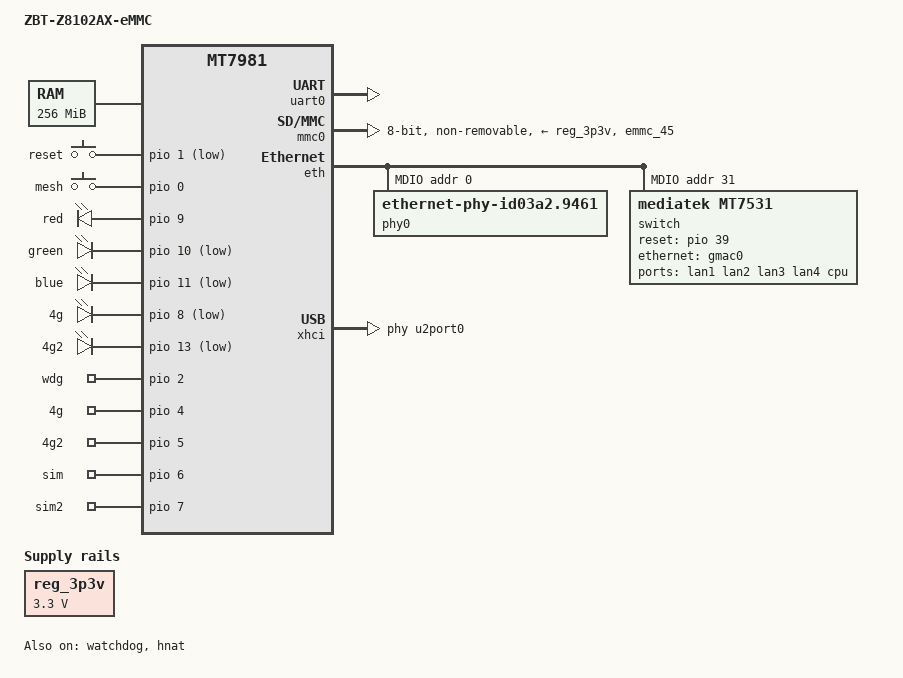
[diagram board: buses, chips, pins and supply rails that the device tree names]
/dts-v1/;
#include "mt7981.dtsi"
/ {

        model = "ZBT-Z8102AX-eMMC";
        compatible = "zbtlink,z8102ax-emmc", "mediatek,mt7981-emmc-rfb";
	chosen {
		bootargs = "console=ttyS0,115200n1 loglevel=8  \
				earlycon=uart8250,mmio32,0x11002000 \
				root=PARTLABEL=rootfs rootfstype=squashfs,f2fs";
	};

	memory {
		// fpga ddr2: 128MB*2
		reg = <0 0x40000000 0 0x10000000>;
	};

        gpio-keys {
                compatible = "gpio-keys";
                reset {
                        label = "reset";
                        linux,code = <KEY_RESTART>;
                        gpios = <&pio 1 GPIO_ACTIVE_LOW>;
                };

                mesh {
                        label = "mesh";
                        linux,code = <BTN_0>;
                        gpios = <&pio 0 GPIO_ACTIVE_HIGH>;
                };

				/*
                hub {
                        label = "hub";
                        linux,code = <BTN_1>;
                        gpios = <&pio 12 GPIO_ACTIVE_HIGH>;
                };
				*/
        };

        gpio-leds {
                compatible = "gpio-leds";
                red {

                        label = "red";
                        gpios = <&pio 9 GPIO_ACTIVE_HIGH>;
                };
                green {

                        label = "green";
                        gpios = <&pio 10 GPIO_ACTIVE_LOW>;
                };
                blue {

                        label = "blue";
                        gpios = <&pio 11 GPIO_ACTIVE_LOW>;
                };
                4g {

                        label = "4g";
                        gpios = <&pio 8 GPIO_ACTIVE_LOW>;
                };
                4g2 {

                        label = "4g2";
                        gpios = <&pio 13 GPIO_ACTIVE_LOW>;
                };
        };

        gpio-export {

                compatible = "gpio-export";
                #size-cells = <0>;

                wdg {
                        gpio-export,name = "wdg";
                        gpio-export,output = <1>;
                        gpios = <&pio 2 GPIO_ACTIVE_HIGH>;
                };
		/*
                pcie {
                        gpio-export,name = "pcie";
                        gpio-export,output = <1>;
                        gpios = <&pio 3 GPIO_ACTIVE_HIGH>;
                };
		*/
                4g {
                        gpio-export,name = "4g";
                        gpio-export,output = <1>;
                        gpios = <&pio 4 GPIO_ACTIVE_HIGH>;
                };
                4g2 {
                        gpio-export,name = "4g2";
                        gpio-export,output = <1>;
                        gpios = <&pio 5 GPIO_ACTIVE_HIGH>;
                };
                sim {
                        gpio-export,name = "sim";
                        gpio-export,output = <1>;
                        gpios = <&pio 6 GPIO_ACTIVE_HIGH>;
                };
                sim2 {
                        gpio-export,name = "sim2";
                        gpio-export,output = <1>;
                        gpios = <&pio 7 GPIO_ACTIVE_HIGH>;
                };
                /*
                hub {
                        gpio-export,name = "hub";
                        gpio-export,input;
                        gpios = <&pio 12 GPIO_ACTIVE_HIGH>;
                };
                */
        };

	reg_3p3v: regulator-3p3v {
		compatible = "regulator-fixed";
		regulator-name = "fixed-3.3V";
		regulator-min-microvolt = <3300000>;
		regulator-max-microvolt = <3300000>;
		regulator-boot-on;
		regulator-always-on;
	};
};

&uart0 {
	status = "okay";
};

&watchdog {
	status = "okay";
};

&mmc0 {
         pinctrl-names = "default", "state_uhs";
         pinctrl-0 = <&mmc0_pins_default>;
         pinctrl-1 = <&mmc0_pins_uhs>;
         bus-width = <8>;
         max-frequency = <52000000>;
         cap-mmc-highspeed;
         vmmc-supply = <&reg_3p3v>;
         non-removable;
         status = "okay";
};

&eth {
	status = "okay";

	gmac0: mac@0 {
		compatible = "mediatek,eth-mac";
		reg = <0>;
		phy-mode = "2500base-x";

		fixed-link {
			speed = <2500>;
			full-duplex;
			pause;
		};
	};

	gmac1: mac@1 {
		compatible = "mediatek,eth-mac";
		reg = <1>;
		phy-mode = "gmii";
		phy-handle = <&phy0>;
	};

	mdio: mdio-bus {
		#address-cells = <1>;
		#size-cells = <0>;

		phy0: ethernet-phy@0 {
			compatible = "ethernet-phy-id03a2.9461";
			reg = <0>;
			phy-mode = "gmii";
			nvmem-cells = <&phy_calibration>;
			nvmem-cell-names = "phy-cal-data";
		};

		switch@0 {
			compatible = "mediatek,mt7531";
			reg = <31>;
			reset-gpios = <&pio 39 0>;

			ports {
				#address-cells = <1>;
				#size-cells = <0>;

				port@0 {
					reg = <0>;
					label = "lan1";
				};

				port@1 {
					reg = <1>;
					label = "lan2";
				};

				port@2 {
					reg = <2>;
					label = "lan3";
				};

				port@3 {
					reg = <3>;
					label = "lan4";
				};

				port@6 {
					reg = <6>;
					label = "cpu";
					ethernet = <&gmac0>;
					phy-mode = "2500base-x";

					fixed-link {
						speed = <2500>;
						full-duplex;
						pause;
					};
				};
			};
		};
	};
};

&hnat {
	mtketh-wan = "eth1";
	mtketh-lan = "lan";
	mtketh-max-gmac = <2>;
	status = "okay";
};

&spi1 {
	pinctrl-names = "default";
	pinctrl-0 = <&spic_pins>;
	status = "disabled";
};

&pio {

	spic_pins: spi1-pins {
		mux {
			function = "spi";
			groups = "spi1_1";
		};
	};

	mmc0_pins_default: mmc0-pins-default {
		mux {
			function = "flash";
			groups = "emmc_45";
		};
	};

	mmc0_pins_uhs: mmc0-pins-uhs {
		mux {
			function = "flash";
			groups = "emmc_45";
		};
	};
};

&xhci {
	mediatek,u3p-dis-msk = <0x0>;
	phys = <&u2port0 PHY_TYPE_USB2>,
	       <&u3port0 PHY_TYPE_USB3>;
	status = "okay";
};
